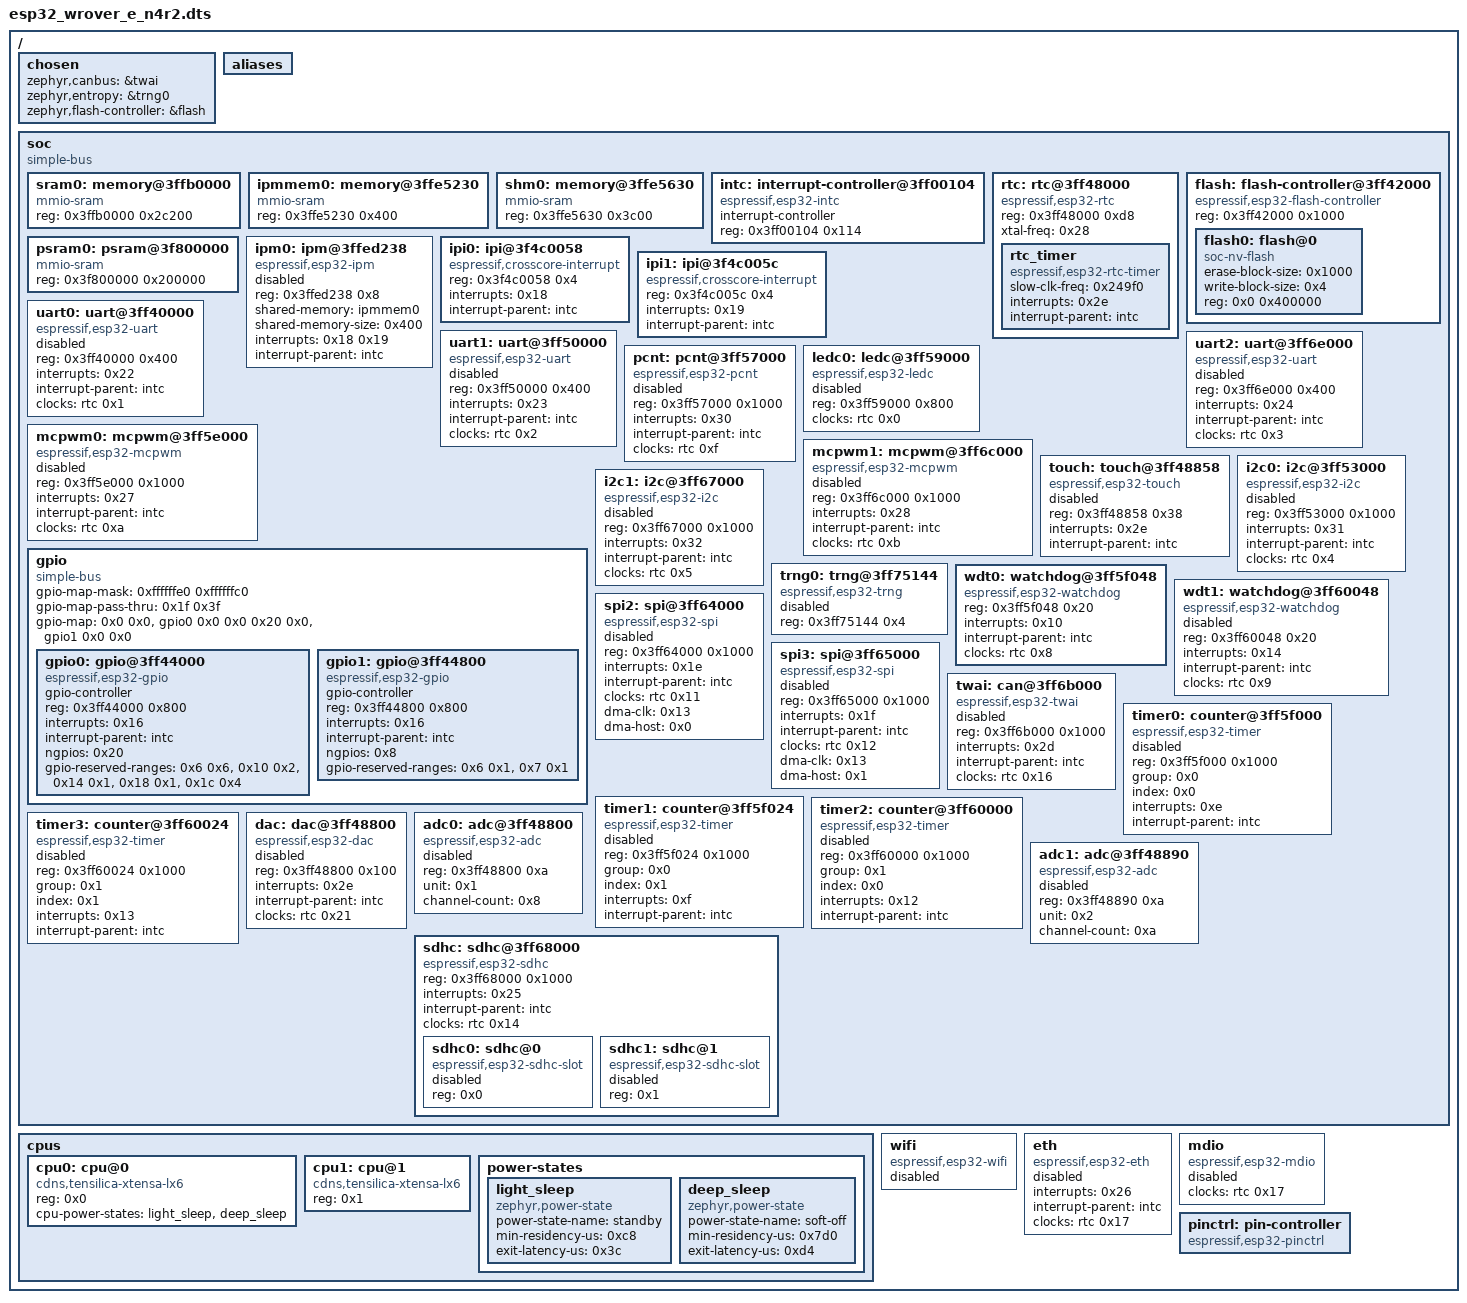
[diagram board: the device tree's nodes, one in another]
/dts-v1/;

/ {
	#address-cells = < 0x1 >;
	#size-cells = < 0x1 >;
	chosen {
		zephyr,canbus = &twai;
		zephyr,entropy = &trng0;
		zephyr,flash-controller = &flash;
	};
	aliases {
	};
	soc {
		#address-cells = < 0x1 >;
		#size-cells = < 0x1 >;
		compatible = "simple-bus";
		ranges;
		sram0: memory@3ffb0000 {
			compatible = "mmio-sram";
			reg = < 0x3ffb0000 0x2c200 >;
		};
		ipmmem0: memory@3ffe5230 {
			compatible = "mmio-sram";
			reg = < 0x3ffe5230 0x400 >;
			phandle = < 0x2 >;
		};
		shm0: memory@3ffe5630 {
			compatible = "mmio-sram";
			reg = < 0x3ffe5630 0x3c00 >;
		};
		intc: interrupt-controller@3ff00104 {
			#interrupt-cells = < 0x1 >;
			compatible = "espressif,esp32-intc";
			interrupt-controller;
			reg = < 0x3ff00104 0x114 >;
			status = "okay";
			phandle = < 0x1 >;
		};
		rtc: rtc@3ff48000 {
			compatible = "espressif,esp32-rtc";
			reg = < 0x3ff48000 0xd8 >;
			xtal-freq = < 0x28 >;
			#clock-cells = < 0x1 >;
			status = "okay";
			phandle = < 0x3 >;
			rtc_timer: rtc_timer {
				compatible = "espressif,esp32-rtc-timer";
				slow-clk-freq = < 0x249f0 >;
				interrupts = < 0x2e >;
				interrupt-parent = < &intc >;
				status = "okay";
			};
		};
		flash: flash-controller@3ff42000 {
			compatible = "espressif,esp32-flash-controller";
			reg = < 0x3ff42000 0x1000 >;
			#address-cells = < 0x1 >;
			#size-cells = < 0x1 >;
			flash0: flash@0 {
				compatible = "soc-nv-flash";
				erase-block-size = < 0x1000 >;
				write-block-size = < 0x4 >;
				reg = < 0x0 0x400000 >;
			};
		};
		psram0: psram@3f800000 {
			device_type = "memory";
			compatible = "mmio-sram";
			reg = < 0x3f800000 0x200000 >;
			status = "okay";
		};
		ipm0: ipm@3ffed238 {
			compatible = "espressif,esp32-ipm";
			reg = < 0x3ffed238 0x8 >;
			status = "disabled";
			shared-memory = < &ipmmem0 >;
			shared-memory-size = < 0x400 >;
			interrupts = < 0x18 0x19 >;
			interrupt-parent = < &intc >;
		};
		ipi0: ipi@3f4c0058 {
			compatible = "espressif,crosscore-interrupt";
			reg = < 0x3f4c0058 0x4 >;
			interrupts = < 0x18 >;
			interrupt-parent = < &intc >;
		};
		ipi1: ipi@3f4c005c {
			compatible = "espressif,crosscore-interrupt";
			reg = < 0x3f4c005c 0x4 >;
			interrupts = < 0x19 >;
			interrupt-parent = < &intc >;
		};
		uart0: uart@3ff40000 {
			compatible = "espressif,esp32-uart";
			reg = < 0x3ff40000 0x400 >;
			interrupts = < 0x22 >;
			interrupt-parent = < &intc >;
			clocks = < &rtc 0x1 >;
			status = "disabled";
		};
		uart1: uart@3ff50000 {
			compatible = "espressif,esp32-uart";
			reg = < 0x3ff50000 0x400 >;
			interrupts = < 0x23 >;
			interrupt-parent = < &intc >;
			clocks = < &rtc 0x2 >;
			status = "disabled";
		};
		uart2: uart@3ff6e000 {
			compatible = "espressif,esp32-uart";
			reg = < 0x3ff6e000 0x400 >;
			interrupts = < 0x24 >;
			interrupt-parent = < &intc >;
			clocks = < &rtc 0x3 >;
			status = "disabled";
		};
		pcnt: pcnt@3ff57000 {
			compatible = "espressif,esp32-pcnt";
			reg = < 0x3ff57000 0x1000 >;
			interrupts = < 0x30 >;
			interrupt-parent = < &intc >;
			clocks = < &rtc 0xf >;
			status = "disabled";
		};
		ledc0: ledc@3ff59000 {
			compatible = "espressif,esp32-ledc";
			#pwm-cells = < 0x3 >;
			reg = < 0x3ff59000 0x800 >;
			clocks = < &rtc 0x0 >;
			status = "disabled";
		};
		mcpwm0: mcpwm@3ff5e000 {
			compatible = "espressif,esp32-mcpwm";
			reg = < 0x3ff5e000 0x1000 >;
			interrupts = < 0x27 >;
			interrupt-parent = < &intc >;
			clocks = < &rtc 0xa >;
			#pwm-cells = < 0x3 >;
			status = "disabled";
		};
		mcpwm1: mcpwm@3ff6c000 {
			compatible = "espressif,esp32-mcpwm";
			reg = < 0x3ff6c000 0x1000 >;
			interrupts = < 0x28 >;
			interrupt-parent = < &intc >;
			clocks = < &rtc 0xb >;
			#pwm-cells = < 0x3 >;
			status = "disabled";
		};
		gpio: gpio {
			compatible = "simple-bus";
			gpio-map-mask = < 0xffffffe0 0xffffffc0 >;
			gpio-map-pass-thru = < 0x1f 0x3f >;
			gpio-map = < 0x0 0x0 &gpio0 0x0 0x0 0x20 0x0 &gpio1 0x0 0x0 >;
			#gpio-cells = < 0x2 >;
			#address-cells = < 0x1 >;
			#size-cells = < 0x1 >;
			ranges;
			gpio0: gpio@3ff44000 {
				compatible = "espressif,esp32-gpio";
				gpio-controller;
				#gpio-cells = < 0x2 >;
				reg = < 0x3ff44000 0x800 >;
				interrupts = < 0x16 >;
				interrupt-parent = < &intc >;
				ngpios = < 0x20 >;
				gpio-reserved-ranges = < 0x6 0x6 >, < 0x10 0x2 >, < 0x14 0x1 >, < 0x18 0x1 >, < 0x1c 0x4 >;
				phandle = < 0x4 >;
			};
			gpio1: gpio@3ff44800 {
				compatible = "espressif,esp32-gpio";
				gpio-controller;
				#gpio-cells = < 0x2 >;
				reg = < 0x3ff44800 0x800 >;
				interrupts = < 0x16 >;
				interrupt-parent = < &intc >;
				ngpios = < 0x8 >;
				gpio-reserved-ranges = < 0x6 0x1 >, < 0x7 0x1 >;
				phandle = < 0x5 >;
			};
		};
		touch: touch@3ff48858 {
			compatible = "espressif,esp32-touch";
			reg = < 0x3ff48858 0x38 >;
			interrupts = < 0x2e >;
			interrupt-parent = < &intc >;
			status = "disabled";
		};
		i2c0: i2c@3ff53000 {
			compatible = "espressif,esp32-i2c";
			#address-cells = < 0x1 >;
			#size-cells = < 0x0 >;
			reg = < 0x3ff53000 0x1000 >;
			interrupts = < 0x31 >;
			interrupt-parent = < &intc >;
			clocks = < &rtc 0x4 >;
			status = "disabled";
		};
		i2c1: i2c@3ff67000 {
			compatible = "espressif,esp32-i2c";
			#address-cells = < 0x1 >;
			#size-cells = < 0x0 >;
			reg = < 0x3ff67000 0x1000 >;
			interrupts = < 0x32 >;
			interrupt-parent = < &intc >;
			clocks = < &rtc 0x5 >;
			status = "disabled";
		};
		trng0: trng@3ff75144 {
			compatible = "espressif,esp32-trng";
			reg = < 0x3ff75144 0x4 >;
			status = "disabled";
		};
		wdt0: watchdog@3ff5f048 {
			compatible = "espressif,esp32-watchdog";
			reg = < 0x3ff5f048 0x20 >;
			interrupts = < 0x10 >;
			interrupt-parent = < &intc >;
			clocks = < &rtc 0x8 >;
			status = "okay";
		};
		wdt1: watchdog@3ff60048 {
			compatible = "espressif,esp32-watchdog";
			reg = < 0x3ff60048 0x20 >;
			interrupts = < 0x14 >;
			interrupt-parent = < &intc >;
			clocks = < &rtc 0x9 >;
			status = "disabled";
		};
		spi2: spi@3ff64000 {
			compatible = "espressif,esp32-spi";
			reg = < 0x3ff64000 0x1000 >;
			interrupts = < 0x1e >;
			interrupt-parent = < &intc >;
			clocks = < &rtc 0x11 >;
			dma-clk = < 0x13 >;
			dma-host = < 0x0 >;
			status = "disabled";
		};
		spi3: spi@3ff65000 {
			compatible = "espressif,esp32-spi";
			reg = < 0x3ff65000 0x1000 >;
			interrupts = < 0x1f >;
			interrupt-parent = < &intc >;
			clocks = < &rtc 0x12 >;
			dma-clk = < 0x13 >;
			dma-host = < 0x1 >;
			status = "disabled";
		};
		twai: can@3ff6b000 {
			compatible = "espressif,esp32-twai";
			reg = < 0x3ff6b000 0x1000 >;
			interrupts = < 0x2d >;
			interrupt-parent = < &intc >;
			clocks = < &rtc 0x16 >;
			status = "disabled";
		};
		timer0: counter@3ff5f000 {
			compatible = "espressif,esp32-timer";
			reg = < 0x3ff5f000 0x1000 >;
			group = < 0x0 >;
			index = < 0x0 >;
			interrupts = < 0xe >;
			interrupt-parent = < &intc >;
			status = "disabled";
		};
		timer1: counter@3ff5f024 {
			compatible = "espressif,esp32-timer";
			reg = < 0x3ff5f024 0x1000 >;
			group = < 0x0 >;
			index = < 0x1 >;
			interrupts = < 0xf >;
			interrupt-parent = < &intc >;
			status = "disabled";
		};
		timer2: counter@3ff60000 {
			compatible = "espressif,esp32-timer";
			reg = < 0x3ff60000 0x1000 >;
			group = < 0x1 >;
			index = < 0x0 >;
			interrupts = < 0x12 >;
			interrupt-parent = < &intc >;
			status = "disabled";
		};
		timer3: counter@3ff60024 {
			compatible = "espressif,esp32-timer";
			reg = < 0x3ff60024 0x1000 >;
			group = < 0x1 >;
			index = < 0x1 >;
			interrupts = < 0x13 >;
			interrupt-parent = < &intc >;
			status = "disabled";
		};
		dac: dac@3ff48800 {
			compatible = "espressif,esp32-dac";
			reg = < 0x3ff48800 0x100 >;
			interrupts = < 0x2e >;
			interrupt-parent = < &intc >;
			clocks = < &rtc 0x21 >;
			#io-channel-cells = < 0x1 >;
			status = "disabled";
		};
		adc0: adc@3ff48800 {
			compatible = "espressif,esp32-adc";
			reg = < 0x3ff48800 0xa >;
			unit = < 0x1 >;
			channel-count = < 0x8 >;
			#io-channel-cells = < 0x1 >;
			status = "disabled";
		};
		adc1: adc@3ff48890 {
			compatible = "espressif,esp32-adc";
			reg = < 0x3ff48890 0xa >;
			unit = < 0x2 >;
			channel-count = < 0xa >;
			#io-channel-cells = < 0x1 >;
			status = "disabled";
		};
		sdhc: sdhc@3ff68000 {
			compatible = "espressif,esp32-sdhc";
			reg = < 0x3ff68000 0x1000 >;
			interrupts = < 0x25 >;
			interrupt-parent = < &intc >;
			clocks = < &rtc 0x14 >;
			#address-cells = < 0x1 >;
			#size-cells = < 0x0 >;
			sdhc0: sdhc@0 {
				compatible = "espressif,esp32-sdhc-slot";
				reg = < 0x0 >;
				status = "disabled";
			};
			sdhc1: sdhc@1 {
				compatible = "espressif,esp32-sdhc-slot";
				reg = < 0x1 >;
				status = "disabled";
			};
		};
	};
	cpus {
		#address-cells = < 0x1 >;
		#size-cells = < 0x0 >;
		cpu0: cpu@0 {
			device_type = "cpu";
			compatible = "cdns,tensilica-xtensa-lx6";
			reg = < 0x0 >;
			cpu-power-states = < &light_sleep &deep_sleep >;
		};
		cpu1: cpu@1 {
			device_type = "cpu";
			compatible = "cdns,tensilica-xtensa-lx6";
			reg = < 0x1 >;
		};
		power-states {
			light_sleep: light_sleep {
				compatible = "zephyr,power-state";
				power-state-name = "standby";
				min-residency-us = < 0xc8 >;
				exit-latency-us = < 0x3c >;
				phandle = < 0x6 >;
			};
			deep_sleep: deep_sleep {
				compatible = "zephyr,power-state";
				power-state-name = "soft-off";
				min-residency-us = < 0x7d0 >;
				exit-latency-us = < 0xd4 >;
				phandle = < 0x7 >;
			};
		};
	};
	wifi: wifi {
		compatible = "espressif,esp32-wifi";
		status = "disabled";
	};
	eth: eth {
		compatible = "espressif,esp32-eth";
		interrupts = < 0x26 >;
		interrupt-parent = < &intc >;
		clocks = < &rtc 0x17 >;
		status = "disabled";
	};
	mdio: mdio {
		compatible = "espressif,esp32-mdio";
		clocks = < &rtc 0x17 >;
		status = "disabled";
		#address-cells = < 0x1 >;
		#size-cells = < 0x0 >;
	};
	pinctrl: pin-controller {
		compatible = "espressif,esp32-pinctrl";
		status = "okay";
	};
};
